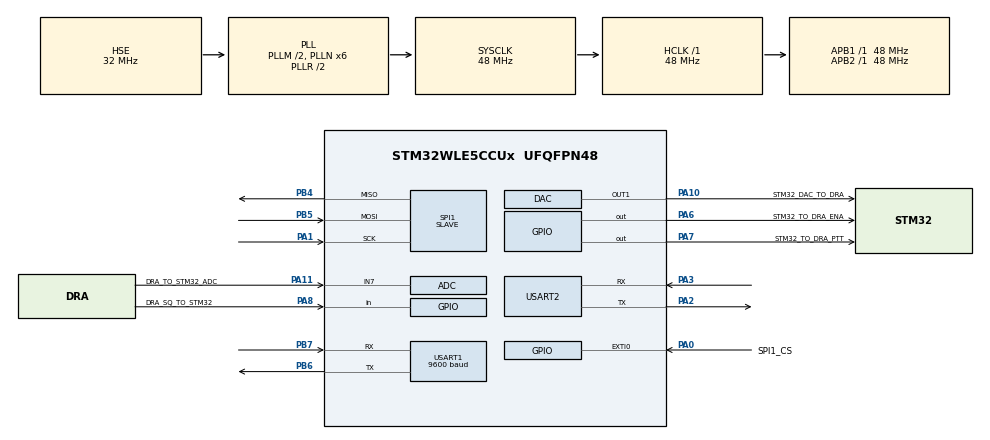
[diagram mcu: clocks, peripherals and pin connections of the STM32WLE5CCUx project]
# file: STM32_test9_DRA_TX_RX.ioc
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ADC.NbrOfConversion=1
ADC.SelectedChannel=ADC_CHANNEL_7
Mcu.Family=STM32WL
Mcu.Name=STM32WLE5CCUx
Mcu.Package=UFQFPN48
NVIC.PriorityGroup=NVIC_PRIORITYGROUP_4
NVIC.SPI1_IRQn=true\:0\:0\:false\:false\:true\:true\:true\:true
NVIC.TIM2_IRQn=true\:0\:0\:false\:false\:true\:true\:true\:true
OSC_IN.Mode=HSE-External-Oscillator
OSC_IN.Signal=RCC_OSC_IN
OSC_OUT.Mode=HSE-External-Oscillator
OSC_OUT.Signal=RCC_OSC_OUT
PA0.GPIO_Label=SPI1_CS
PA0.GPIO_ModeDefaultEXTI=GPIO_MODE_IT_RISING_FALLING
PA0.Signal=GPXTI0
PA1.Mode=Full_Duplex_Slave
PA1.Signal=SPI1_SCK
PA10.GPIO_Label=STM32_DAC_TO_DRA
PA10.Signal=COMP_DAC1_group
PA11.GPIO_Label=DRA_TO_STM32_ADC
PA11.Mode=IN7
PA11.Signal=ADC_IN7
PA13.Mode=Trace_Asynchronous_SW
PA13.Signal=DEBUG_JTMS-SWDIO
PA14.Mode=Trace_Asynchronous_SW
PA14.Signal=DEBUG_JTCK-SWCLK
PA2.Mode=Asynchronous
PA2.Signal=USART2_TX
PA3.Mode=Asynchronous
PA3.Signal=USART2_RX
PA6.GPIO_Label=STM32_TO_DRA_ENA
PA6.Signal=GPIO_Output
PA7.GPIO_Label=STM32_TO_DRA_PTT
PA7.Signal=GPIO_Output
PA8.GPIO_Label=DRA_SQ_TO_STM32
PA8.Signal=GPIO_Input
PB3.Mode=Trace_Asynchronous_SW
PB3.Signal=DEBUG_JTDO-SWO
PB4.Mode=Full_Duplex_Slave
PB4.Signal=SPI1_MISO
PB5.Mode=Full_Duplex_Slave
PB5.Signal=SPI1_MOSI
PB6.Mode=Asynchronous
PB6.Signal=USART1_TX
PB7.Mode=Asynchronous
PB7.Signal=USART1_RX
ProjectManager.HeapSize=0x200
ProjectManager.StackSize=0x400
ProjectManager.TargetToolchain=STM32CubeIDE
RCC.AHBFreq_Value=48000000
RCC.APB1Freq_Value=48000000
RCC.APB1TimFreq_Value=48000000
RCC.APB2Freq_Value=48000000
RCC.APB2TimFreq_Value=48000000
RCC.APB3Freq_Value=48000000
RCC.CortexFreq_Value=48000000
RCC.HCLKFreq_Value=48000000
RCC.HSE_VALUE=32000000
RCC.HSI_VALUE=16000000
RCC.LSE_VALUE=32768
RCC.PLLM=RCC_PLLM_DIV2
RCC.PLLN=6
RCC.PLLSourceVirtual=RCC_PLLSOURCE_HSE
RCC.SYSCLKFreq_VALUE=48000000
RCC.SYSCLKSource=RCC_SYSCLKSOURCE_PLLCLK
RCC.VCOOutputFreq_Value=96000000
SH.COMP_DAC1_group.0=DAC_OUT1,DAC_OUT1
SPI1.DataSize=SPI_DATASIZE_8BIT
SPI1.Direction=SPI_DIRECTION_2LINES
SPI1.Mode=SPI_MODE_SLAVE
SPI1.VirtualType=VM_SLAVE
TIM2.AutoReloadPreload=TIM_AUTORELOAD_PRELOAD_ENABLE
TIM2.Period=4999
USART1.BaudRate=9600
USART1.VirtualMode-Asynchronous=VM_ASYNC
USART2.VirtualMode-Asynchronous=VM_ASYNC
VP_TIM2_VS_ClockSourceINT.Mode=Internal
board=custom

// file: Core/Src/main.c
/* USER CODE BEGIN Header */
/**
  ******************************************************************************
  * @file           : main.c
  * @brief          : Main program body
  ******************************************************************************
  * @attention
  *
  * Copyright (c) 2026 STMicroelectronics.
  * All rights reserved.
  *
  * This software is licensed under terms that can be found in the LICENSE file
  * in the root directory of this software component.
  * If no LICENSE file comes with this software, it is provided AS-IS.
  *
  ******************************************************************************
  */
/* USER CODE END Header */
#include "main.h"
#include "adc.h"
#include "dac.h"
#include "spi.h"
#include "tim.h"
#include "usart.h"
#include "gpio.h"

/* USER CODE BEGIN Includes */
#include "app.h"

/* USER CODE END Includes */

void SystemClock_Config(void);

int main(void)
{

  /* MCU Configuration--------------------------------------------------------*/

  /* Reset of all peripherals, Initializes the Flash interface and the Systick. */
  HAL_Init();

  /* Configure the system clock */
  SystemClock_Config();

  /* Initialize all configured peripherals */
  MX_GPIO_Init();
  MX_SPI1_Init();
  MX_ADC_Init();
  MX_DAC_Init();
  MX_USART1_UART_Init();
  MX_TIM2_Init();
  MX_USART2_UART_Init();
  /* USER CODE BEGIN 2 */
  MX_GPIO_UserPostInit();
  App_Init();

  /* USER CODE END 2 */

  /* Infinite loop */
  while (1)
  {

    /* USER CODE BEGIN 3 */
    App_Run();
  }
  /* USER CODE END 3 */
}

void SystemClock_Config(void)
{
  RCC_OscInitTypeDef RCC_OscInitStruct = {0};
  RCC_ClkInitTypeDef RCC_ClkInitStruct = {0};

  /** Configure the main internal regulator output voltage
  */
  __HAL_PWR_VOLTAGESCALING_CONFIG(PWR_REGULATOR_VOLTAGE_SCALE1);

  /** Initializes the CPU, AHB and APB buses clocks
  */
  RCC_OscInitStruct.OscillatorType = RCC_OSCILLATORTYPE_HSE;
  RCC_OscInitStruct.HSEState = RCC_HSE_ON;
  RCC_OscInitStruct.HSEDiv = RCC_HSE_DIV1;
  RCC_OscInitStruct.PLL.PLLState = RCC_PLL_ON;
  RCC_OscInitStruct.PLL.PLLSource = RCC_PLLSOURCE_HSE;
  RCC_OscInitStruct.PLL.PLLM = RCC_PLLM_DIV2;
  RCC_OscInitStruct.PLL.PLLN = 6;
  RCC_OscInitStruct.PLL.PLLP = RCC_PLLP_DIV2;
  RCC_OscInitStruct.PLL.PLLR = RCC_PLLR_DIV2;
  RCC_OscInitStruct.PLL.PLLQ = RCC_PLLQ_DIV2;
  if (HAL_RCC_OscConfig(&RCC_OscInitStruct) != HAL_OK)
  {
    Error_Handler();
  }

  /** Configure the SYSCLKSource, HCLK, PCLK1 and PCLK2 clocks dividers
  */
  RCC_ClkInitStruct.ClockType = RCC_CLOCKTYPE_HCLK3|RCC_CLOCKTYPE_HCLK
                              |RCC_CLOCKTYPE_SYSCLK|RCC_CLOCKTYPE_PCLK1
                              |RCC_CLOCKTYPE_PCLK2;
  RCC_ClkInitStruct.SYSCLKSource = RCC_SYSCLKSOURCE_PLLCLK;
  RCC_ClkInitStruct.AHBCLKDivider = RCC_SYSCLK_DIV1;
  RCC_ClkInitStruct.APB1CLKDivider = RCC_HCLK_DIV1;
  RCC_ClkInitStruct.APB2CLKDivider = RCC_HCLK_DIV1;
  RCC_ClkInitStruct.AHBCLK3Divider = RCC_SYSCLK_DIV1;

  if (HAL_RCC_ClockConfig(&RCC_ClkInitStruct, FLASH_LATENCY_2) != HAL_OK)
  {
    Error_Handler();
  }
}

void Error_Handler(void)
{
  __disable_irq();
  while (1)
  {
  }
}
